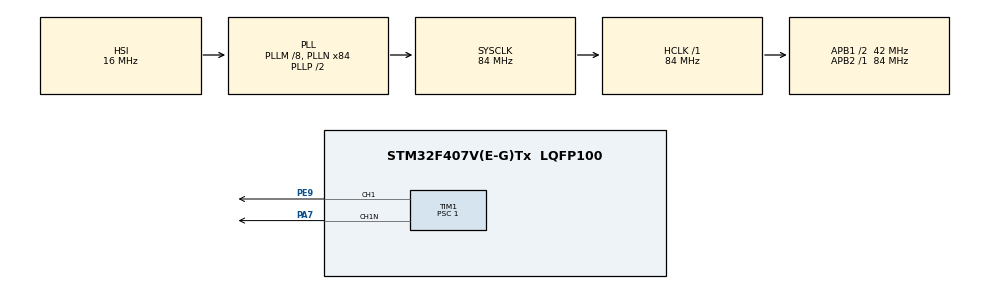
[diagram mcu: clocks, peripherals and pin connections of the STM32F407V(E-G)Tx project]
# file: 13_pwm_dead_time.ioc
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Mcu.Family=STM32F4
Mcu.Name=STM32F407V(E-G)Tx
Mcu.Package=LQFP100
NVIC.PriorityGroup=NVIC_PRIORITYGROUP_4
PA13.Mode=Serial_Wire
PA13.Signal=SYS_JTMS-SWDIO
PA14.Mode=Serial_Wire
PA14.Signal=SYS_JTCK-SWCLK
PA7.Mode=PWM Generation1 CH1 CH1N
PA7.Signal=TIM1_CH1N
PE9.Signal=S_TIM1_CH1
ProjectManager.HeapSize=0x200
ProjectManager.StackSize=0x400
ProjectManager.TargetToolchain=MDK-ARM V5
RCC.48MHZClocksFreq_Value=42000000
RCC.AHBFreq_Value=84000000
RCC.APB1CLKDivider=RCC_HCLK_DIV2
RCC.APB1Freq_Value=42000000
RCC.APB1TimFreq_Value=84000000
RCC.APB2Freq_Value=84000000
RCC.APB2TimFreq_Value=84000000
RCC.CortexFreq_Value=84000000
RCC.HCLKFreq_Value=84000000
RCC.HSE_VALUE=25000000
RCC.HSI_VALUE=16000000
RCC.LSE_VALUE=32768
RCC.PLLM=8
RCC.PLLN=84
RCC.SYSCLKFreq_VALUE=84000000
RCC.SYSCLKSource=RCC_SYSCLKSOURCE_PLLCLK
RCC.VCOOutputFreq_Value=168000000
SH.S_TIM1_CH1.0=TIM1_CH1,PWM Generation1 CH1 CH1N
TIM1.Channel-PWM\ Generation1\ CH1\ CH1N=TIM_CHANNEL_1
TIM1.DeadTime=250
TIM1.Period=4199
TIM1.Prescaler=1
VP_TIM1_VS_ClockSourceINT.Mode=Internal
board=13_pwm_dead_time

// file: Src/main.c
/**
  ******************************************************************************
  * File Name          : main.c
  * Description        : Main program body
  ******************************************************************************
  ** This notice applies to any and all portions of this file
  * that are not between comment pairs USER CODE BEGIN and
  * USER CODE END. Other portions of this file, whether
  * inserted by the user or by software development tools
  * are owned by their respective copyright owners.
  *
  * COPYRIGHT(c) 2018 STMicroelectronics
  *
  * Redistribution and use in source and binary forms, with or without modification,
  * are permitted provided that the following conditions are met:
  *   1. Redistributions of source code must retain the above copyright notice,
  *      this list of conditions and the following disclaimer.
  *   2. Redistributions in binary form must reproduce the above copyright notice,
  *      this list of conditions and the following disclaimer in the documentation
  *      and/or other materials provided with the distribution.
  *   3. Neither the name of STMicroelectronics nor the names of its contributors
  *      may be used to endorse or promote products derived from this software
  *      without specific prior written permission.
  *
  * THIS SOFTWARE IS PROVIDED BY THE COPYRIGHT HOLDERS AND CONTRIBUTORS "AS IS"
  * AND ANY EXPRESS OR IMPLIED WARRANTIES, INCLUDING, BUT NOT LIMITED TO, THE
  * IMPLIED WARRANTIES OF MERCHANTABILITY AND FITNESS FOR A PARTICULAR PURPOSE ARE
  * DISCLAIMED. IN NO EVENT SHALL THE COPYRIGHT HOLDER OR CONTRIBUTORS BE LIABLE
  * FOR ANY DIRECT, INDIRECT, INCIDENTAL, SPECIAL, EXEMPLARY, OR CONSEQUENTIAL
  * DAMAGES (INCLUDING, BUT NOT LIMITED TO, PROCUREMENT OF SUBSTITUTE GOODS OR
  * SERVICES; LOSS OF USE, DATA, OR PROFITS; OR BUSINESS INTERRUPTION) HOWEVER
  * CAUSED AND ON ANY THEORY OF LIABILITY, WHETHER IN CONTRACT, STRICT LIABILITY,
  * OR TORT (INCLUDING NEGLIGENCE OR OTHERWISE) ARISING IN ANY WAY OUT OF THE USE
  * OF THIS SOFTWARE, EVEN IF ADVISED OF THE POSSIBILITY OF SUCH DAMAGE.
  *
  ******************************************************************************
  */
#include "main.h"
#include "stm32f4xx_hal.h"

TIM_HandleTypeDef htim1;

/* USER CODE BEGIN PV */
/* Private variables ---------------------------------------------------------*/

/* USER CODE END PV */

void SystemClock_Config(void);
static void MX_GPIO_Init(void);
static void MX_TIM1_Init(void);
void HAL_TIM_MspPostInit(TIM_HandleTypeDef *htim);

/* USER CODE BEGIN PFP */
/* Private function prototypes -----------------------------------------------*/

/* USER CODE END PFP */

int main(void)
{

  /* MCU Configuration----------------------------------------------------------*/

  /* Reset of all peripherals, Initializes the Flash interface and the Systick. */
  HAL_Init();

  /* Configure the system clock */
  SystemClock_Config();

  /* Initialize all configured peripherals */
  MX_GPIO_Init();
  MX_TIM1_Init();

  /* USER CODE BEGIN 2 */

/* start pwm outputs CH1 and CH1N */

   HAL_TIM_PWM_Start(&htim1,TIM_CHANNEL_1);
   HAL_TIMEx_PWMN_Start(&htim1,TIM_CHANNEL_1);
  // pwm ler aktif  ch1 ve ch1n

  /* USER CODE END 2 */

  /* Infinite loop */
  /* USER CODE BEGIN WHILE */
  while (1)
  {
  /* 10kHZ lik sinyal etmek istiyoruz  */
   /*
		set pwm duty cycle
		Timer1 APB2 Timer Clock; Timer_Clk=84000000 MHZ ,Prescaler=1
		Timer_Tick_Freq = Timer_Clk /(Prescaler+1));
		PWM_Freq= Timer_Tick_Freq /(Period+1);
		Period = (Timer_Tick_Freq/PWM_Freq)-1;

		Timer_Tick_Freq= 84000000/(1+1)= 42000000 MHZ
		For 10kHZ frequency,  Period =(42000000/10000) -1 =4199 (ARR Value)

		%40 duty cycle;  pulse=((4199+1)*40)/100 -1 =1679

		Dead Time ; 0-250

		*/
		uint16_t pulse=1679;

		__HAL_TIM_SetCompare(&htim1,TIM_CHANNEL_1,pulse);

		// % 40 lik duyt cycle ayarladik..
		// birini setlemek yetiyor çünkü complementary output...
		// Dead Time fig 120,121,122 look

  }
  /* USER CODE END 3 */

}

/** System Clock Configuration
*/
void SystemClock_Config(void)
{

  RCC_OscInitTypeDef RCC_OscInitStruct;
  RCC_ClkInitTypeDef RCC_ClkInitStruct;

    /**Configure the main internal regulator output voltage
    */
  __HAL_RCC_PWR_CLK_ENABLE();

  __HAL_PWR_VOLTAGESCALING_CONFIG(PWR_REGULATOR_VOLTAGE_SCALE1);

    /**Initializes the CPU, AHB and APB busses clocks
    */
  RCC_OscInitStruct.OscillatorType = RCC_OSCILLATORTYPE_HSI;
  RCC_OscInitStruct.HSIState = RCC_HSI_ON;
  RCC_OscInitStruct.HSICalibrationValue = 16;
  RCC_OscInitStruct.PLL.PLLState = RCC_PLL_ON;
  RCC_OscInitStruct.PLL.PLLSource = RCC_PLLSOURCE_HSI;
  RCC_OscInitStruct.PLL.PLLM = 8;
  RCC_OscInitStruct.PLL.PLLN = 84;
  RCC_OscInitStruct.PLL.PLLP = RCC_PLLP_DIV2;
  RCC_OscInitStruct.PLL.PLLQ = 4;
  if (HAL_RCC_OscConfig(&RCC_OscInitStruct) != HAL_OK)
  {
    _Error_Handler(__FILE__, __LINE__);
  }

    /**Initializes the CPU, AHB and APB busses clocks
    */
  RCC_ClkInitStruct.ClockType = RCC_CLOCKTYPE_HCLK|RCC_CLOCKTYPE_SYSCLK
                              |RCC_CLOCKTYPE_PCLK1|RCC_CLOCKTYPE_PCLK2;
  RCC_ClkInitStruct.SYSCLKSource = RCC_SYSCLKSOURCE_PLLCLK;
  RCC_ClkInitStruct.AHBCLKDivider = RCC_SYSCLK_DIV1;
  RCC_ClkInitStruct.APB1CLKDivider = RCC_HCLK_DIV2;
  RCC_ClkInitStruct.APB2CLKDivider = RCC_HCLK_DIV1;

  if (HAL_RCC_ClockConfig(&RCC_ClkInitStruct, FLASH_LATENCY_2) != HAL_OK)
  {
    _Error_Handler(__FILE__, __LINE__);
  }

    /**Configure the Systick interrupt time
    */
  HAL_SYSTICK_Config(HAL_RCC_GetHCLKFreq()/1000);

    /**Configure the Systick
    */
  HAL_SYSTICK_CLKSourceConfig(SYSTICK_CLKSOURCE_HCLK);

  /* SysTick_IRQn interrupt configuration */
  HAL_NVIC_SetPriority(SysTick_IRQn, 0, 0);
}

/* TIM1 init function */
static void MX_TIM1_Init(void)
{

  TIM_ClockConfigTypeDef sClockSourceConfig;
  TIM_MasterConfigTypeDef sMasterConfig;
  TIM_OC_InitTypeDef sConfigOC;
  TIM_BreakDeadTimeConfigTypeDef sBreakDeadTimeConfig;

  htim1.Instance = TIM1;
  htim1.Init.Prescaler = 1;
  htim1.Init.CounterMode = TIM_COUNTERMODE_UP;
  htim1.Init.Period = 4199;
  htim1.Init.ClockDivision = TIM_CLOCKDIVISION_DIV1;
  htim1.Init.RepetitionCounter = 0;
  if (HAL_TIM_Base_Init(&htim1) != HAL_OK)
  {
    _Error_Handler(__FILE__, __LINE__);
  }

  sClockSourceConfig.ClockSource = TIM_CLOCKSOURCE_INTERNAL;
  if (HAL_TIM_ConfigClockSource(&htim1, &sClockSourceConfig) != HAL_OK)
  {
    _Error_Handler(__FILE__, __LINE__);
  }

  if (HAL_TIM_PWM_Init(&htim1) != HAL_OK)
  {
    _Error_Handler(__FILE__, __LINE__);
  }

  sMasterConfig.MasterOutputTrigger = TIM_TRGO_RESET;
  sMasterConfig.MasterSlaveMode = TIM_MASTERSLAVEMODE_DISABLE;
  if (HAL_TIMEx_MasterConfigSynchronization(&htim1, &sMasterConfig) != HAL_OK)
  {
    _Error_Handler(__FILE__, __LINE__);
  }

  sConfigOC.OCMode = TIM_OCMODE_PWM1;
  sConfigOC.Pulse = 0;
  sConfigOC.OCPolarity = TIM_OCPOLARITY_HIGH;
  sConfigOC.OCNPolarity = TIM_OCNPOLARITY_HIGH;
  sConfigOC.OCFastMode = TIM_OCFAST_DISABLE;
  sConfigOC.OCIdleState = TIM_OCIDLESTATE_RESET;
  sConfigOC.OCNIdleState = TIM_OCNIDLESTATE_RESET;
  if (HAL_TIM_PWM_ConfigChannel(&htim1, &sConfigOC, TIM_CHANNEL_1) != HAL_OK)
  {
    _Error_Handler(__FILE__, __LINE__);
  }

  sBreakDeadTimeConfig.OffStateRunMode = TIM_OSSR_DISABLE;
  sBreakDeadTimeConfig.OffStateIDLEMode = TIM_OSSI_DISABLE;
  sBreakDeadTimeConfig.LockLevel = TIM_LOCKLEVEL_OFF;
  sBreakDeadTimeConfig.DeadTime = 250;
  sBreakDeadTimeConfig.BreakState = TIM_BREAK_DISABLE;
  sBreakDeadTimeConfig.BreakPolarity = TIM_BREAKPOLARITY_HIGH;
  sBreakDeadTimeConfig.AutomaticOutput = TIM_AUTOMATICOUTPUT_DISABLE;
  if (HAL_TIMEx_ConfigBreakDeadTime(&htim1, &sBreakDeadTimeConfig) != HAL_OK)
  {
    _Error_Handler(__FILE__, __LINE__);
  }

  HAL_TIM_MspPostInit(&htim1);

}

/** Configure pins as
        * Analog
        * Input
        * Output
        * EVENT_OUT
        * EXTI
*/
static void MX_GPIO_Init(void)
{

  /* GPIO Ports Clock Enable */
  __HAL_RCC_GPIOA_CLK_ENABLE();
  __HAL_RCC_GPIOE_CLK_ENABLE();

}

void _Error_Handler(char * file, int line)
{
  while(1)
  {
  }
}

/************************ (C) COPYRIGHT STMicroelectronics *****END OF FILE****/
